# HSI_TOP register map
Vendor: Texas Instruments
Peripheral module from a debugger description file (folder omap4460).
Registers are 32-bit, access per field, reset 0x0 unless marked. A register's access mark holds for its fields unless they carry their own. Offsets are as the file gives them; lines under a group give offsets from that group; [hi:lo] are bit positions; {n}, {i} and the like mark numbered series; 'fields as' and 'values as' point back to an identical list; <NAME> marks a mode.

## HSI_TOP
0x00 HSI_REVISION ro reset not defined — IP Revision Identifier (X.Y.R)Used by software to track features, bugs, and compatibility
  [31:0] REVISION — IP Revision
0x04 HSI_HWINFO ro reset not defined — Information about the IP module's hardware configuration, i.e. typically the module's HDL generics (if any).Actual field format and encoding is decided by the module's designer.
  [31:0] HWINFO — IP module hardware configuration
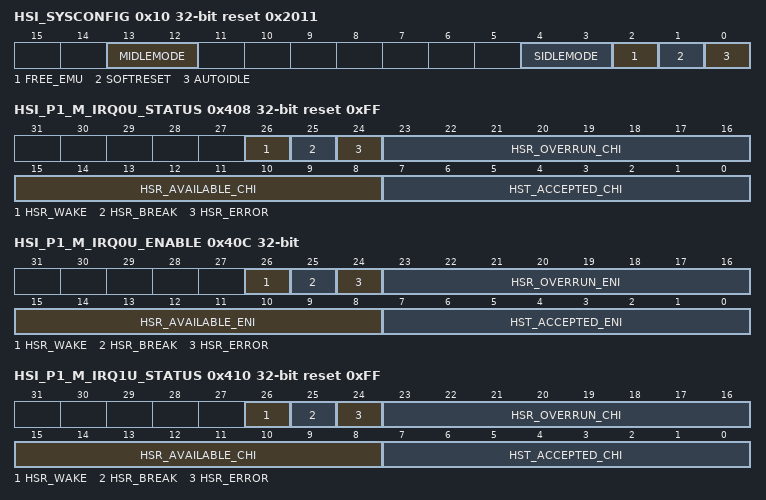
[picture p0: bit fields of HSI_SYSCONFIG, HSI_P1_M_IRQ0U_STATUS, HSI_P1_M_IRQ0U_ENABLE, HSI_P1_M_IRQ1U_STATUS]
0x10 HSI_SYSCONFIG reset 0x2011 — This register allows controlling various parameters of the L4_CFG interface
  [13:12] MIDLEMODE rw — Master interface power management, standby/wait control
    0=force standby; 1=no standby; 2=smart standby; 3=smart standby wakeup
  [4:3] SIDLEMODE rw — Slave interface power management, request/acknowledgement control
    0=force idle; 1=no idle; 2=smart idle; 3=smart idle wakeup
  [2] FREE_EMU rw — Sensitivity to emulation (debug) suspend input signal
    0=module is sensitive to emulation suspend; 1=module is not sensitive to emulation suspend
  [1] SOFTRESET rw — Software reset
    0=no reset applied; 1=Software reset applied
  [0] AUTOIDLE rw — Internal interface clock gating strategy
    0=interface clock is free-running; 1=automatic interface clock gating strategy, based on interconnect interface activity
0x14 HSI_SYSSTATUS ro reset 0x1 — Status on module, (reset done on bit 0, available for more status info)
  [31:0] RESETDONE — Internal reset monitoring
    0=RESETDONE_0_r (internal reset is ongoing); 1=RESETDONE_1_r (internal reset is completed and the module is ready to be used)
0x408 HSI_P1_M_IRQ0U_STATUS reset 0xFF — IRQ status register for FIFO (8..15) events and for port p break, wake and error events. Events will signal interrupt for DSP line r (Dspirq_r)Read 0: event has not occurredRead 1: event has occurredWrite 0: bit stays unchangedWrite 1: bit gets reset to 0
  [26] HSR_WAKE rw — Wake detected on any channel 8..15
  [25] HSR_BREAK rw — Break detected on any channel 8..15
  [24] HSR_ERROR rw — Error detected on any channel 8..15
  [23:16] HSR_OVERRUN_CHI rw — Data overrun in real time mode channel 8..15 (LSB stands for channel 8 and MSB for channel 15).
  [15:8] HSR_AVAILABLE_CHI rw — Data received on channel 8..15 (LSB stands for channel 8 and MSB for channel 15)
  [7:0] HST_ACCEPTED_CHI rw — Data transmitted on channel 8..15 (LSB stands for channel 8 and MSB for channel 15)
0x40C HSI_P1_M_IRQ0U_ENABLE — IRQ enable register for FIFO (8..15) events and for port p break, wake and error events signaled to DSP line r (Dspirq_r)Write 0: event is maskedWrite 1: event is enabled
  [26] HSR_WAKE rw — Wake interrupt enable for all channels 8..15
  [25] HSR_BREAK rw — Break interrupt enable for all channels 8..15
  [24] HSR_ERROR rw — Error interrupt enable for all channels 8..15
  [23:16] HSR_OVERRUN_ENI rw — Overrun interrupt enable for channel 8..15 (LSB stands for channel 8 and MSB for channel 15)
  [15:8] HSR_AVAILABLE_ENI rw — Data available interrupt enable for channel 8..15 (LSB stands for channel 8 and MSB for channel 15)
  [7:0] HST_ACCEPTED_ENI rw — Data accepted interrupt enable for channel 8..15 (LSB stands for channel 8 and MSB for channel 15)
0x410 HSI_P1_M_IRQ1U_STATUS reset 0xFF — IRQ status register for FIFO (8..15) events and for port p break, wake and error events. Events will signal interrupt for DSP line r (Dspirq_r)Read 0: event has not occurredRead 1: event has occurredWrite 0: bit stays unchangedWrite 1: bit gets reset to 0
  fields as HSI_P1_M_IRQ0U_STATUS
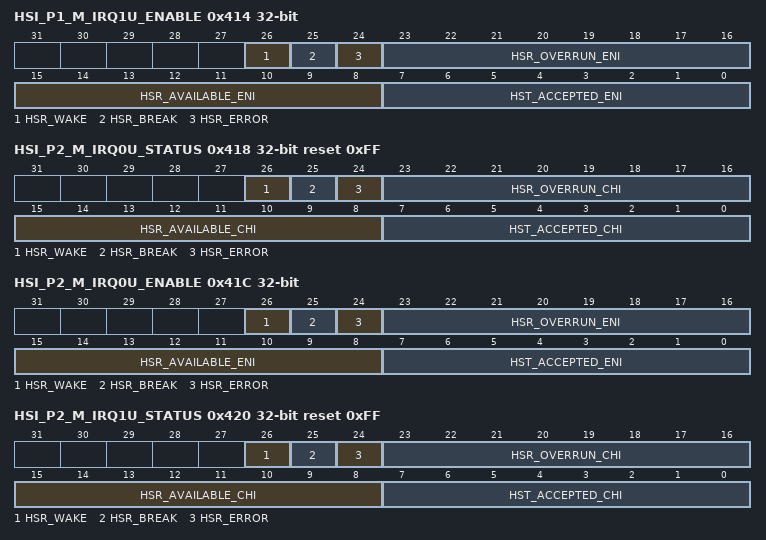
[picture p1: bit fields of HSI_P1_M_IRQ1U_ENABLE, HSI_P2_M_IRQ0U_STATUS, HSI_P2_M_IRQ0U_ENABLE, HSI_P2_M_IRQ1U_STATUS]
0x414 HSI_P1_M_IRQ1U_ENABLE — IRQ enable register for FIFO (8..15) events and for port p break, wake and error events signaled to DSP line r (Dspirq_r)Write 0: event is maskedWrite 1: event is enabled
  fields as HSI_P1_M_IRQ0U_ENABLE
0x418 HSI_P2_M_IRQ0U_STATUS reset 0xFF — IRQ status register for FIFO (8..15) events and for port p break, wake and error events. Events will signal interrupt for DSP line r (Dspirq_r)Read 0: event has not occurredRead 1: event has occurredWrite 0: bit stays unchangedWrite 1: bit gets reset to 0
  fields as HSI_P1_M_IRQ0U_STATUS
0x41C HSI_P2_M_IRQ0U_ENABLE — IRQ enable register for FIFO (8..15) events and for port p break, wake and error events signaled to DSP line r (Dspirq_r)Write 0: event is maskedWrite 1: event is enabled
  fields as HSI_P1_M_IRQ0U_ENABLE
0x420 HSI_P2_M_IRQ1U_STATUS reset 0xFF — IRQ status register for FIFO (8..15) events and for port p break, wake and error events. Events will signal interrupt for DSP line r (Dspirq_r)Read 0: event has not occurredRead 1: event has occurredWrite 0: bit stays unchangedWrite 1: bit gets reset to 0
  fields as HSI_P1_M_IRQ0U_STATUS
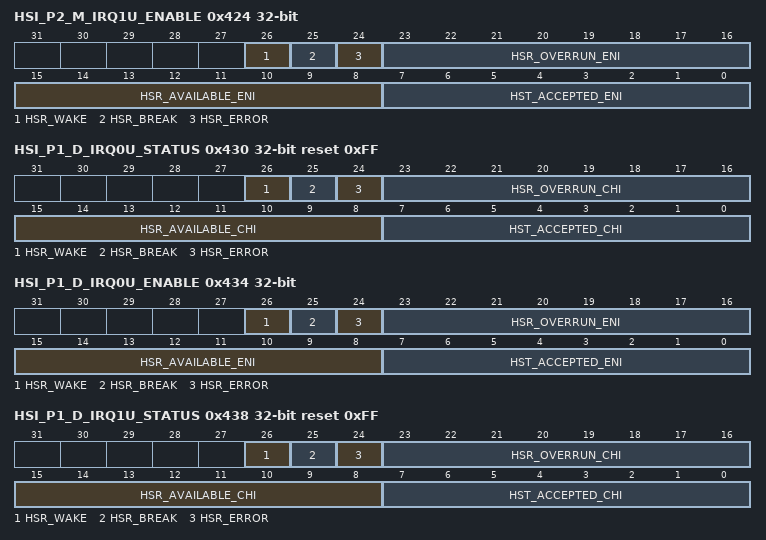
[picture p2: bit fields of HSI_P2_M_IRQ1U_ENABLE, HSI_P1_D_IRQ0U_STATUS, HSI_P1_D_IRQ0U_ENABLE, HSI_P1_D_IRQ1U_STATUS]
0x424 HSI_P2_M_IRQ1U_ENABLE — IRQ enable register for FIFO (8..15) events and for port p break, wake and error events signaled to DSP line r (Dspirq_r)Write 0: event is maskedWrite 1: event is enabled
  fields as HSI_P1_M_IRQ0U_ENABLE
0x430 HSI_P1_D_IRQ0U_STATUS reset 0xFF — IRQ status register for FIFO (8..15) events and for port p break, wake and error events. Events will signal interrupt for DSP line r (Dspirq_r)Read 0: event has not occurredRead 1: event has occurredWrite 0: bit stays unchangedWrite 1: bit gets reset to 0
  [26] HSR_WAKE rw — Wake detected on any channel 8..15
  [25] HSR_BREAK rw — Break detected on any channel 8..15
  [24] HSR_ERROR rw — Error on any channel 8..15
  [23:16] HSR_OVERRUN_CHI rw — Data overrun in real time mode channel 8..15 (LSB stands for channel 8 and MSB for channel 15)
  [15:8] HSR_AVAILABLE_CHI rw — Data received on channel 8..15 (LSB stands for channel 8 and MSB for channel 15)
  [7:0] HST_ACCEPTED_CHI rw — Data transmitted on channel 8..15 (LSB stands for channel 8 and MSB for channel 15)
0x434 HSI_P1_D_IRQ0U_ENABLE — IRQ enable register for FIFO (8..15) events and for port p break, wake and error events signaled to DSP line r (Dspirq_r)Write 0: event is maskedWrite 1: event is enabled
  [26] HSR_WAKE rw — Wake interrupt enable for channel 8..15
  [25] HSR_BREAK rw — Break interrupt enable for channel 8..15
  [24] HSR_ERROR rw — Error interrupt enable for channel 8..15
  [23:16] HSR_OVERRUN_ENI rw — Overrun interrupt enable for channel 8..15
  [15:8] HSR_AVAILABLE_ENI rw — Data available interrupt enable for channel 8..15 (LSB stands for channel 8 and MSB for channel 15)
  [7:0] HST_ACCEPTED_ENI rw — Data accepted interrupt enable for channel 8..15 (LSB stands for channel 8 and MSB for channel 15)
0x438 HSI_P1_D_IRQ1U_STATUS reset 0xFF — IRQ status register for FIFO (8..15) events and for port p break, wake and error events. Events will signal interrupt for DSP line r (Dspirq_r)Read 0: event has not occurredRead 1: event has occurredWrite 0: bit stays unchangedWrite 1: bit gets reset to 0
  fields as HSI_P1_D_IRQ0U_STATUS
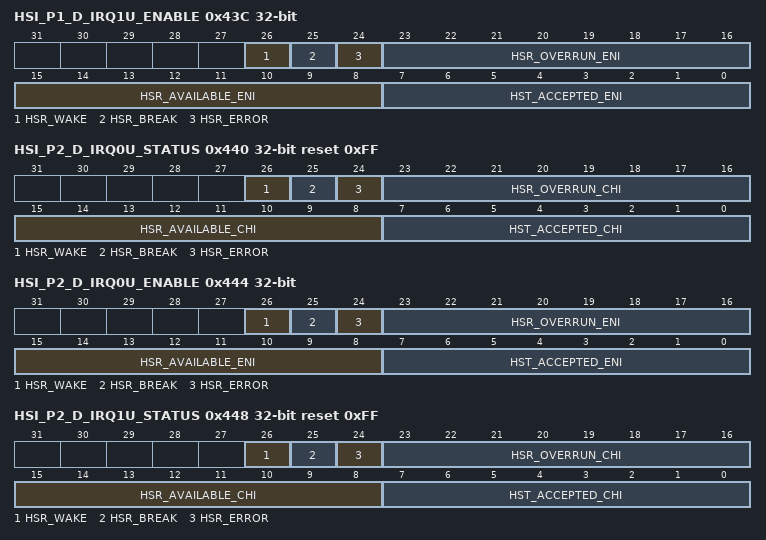
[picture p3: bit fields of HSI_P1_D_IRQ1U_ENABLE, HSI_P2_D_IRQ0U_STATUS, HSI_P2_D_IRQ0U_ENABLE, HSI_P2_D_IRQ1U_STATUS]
0x43C HSI_P1_D_IRQ1U_ENABLE — IRQ enable register for FIFO (8..15) events and for port p break, wake and error events signaled to DSP line r (Dspirq_r)Write 0: event is maskedWrite 1: event is enabled
  fields as HSI_P1_D_IRQ0U_ENABLE
0x440 HSI_P2_D_IRQ0U_STATUS reset 0xFF — IRQ status register for FIFO (8..15) events and for port p break, wake and error events. Events will signal interrupt for DSP line r (Dspirq_r)Read 0: event has not occurredRead 1: event has occurredWrite 0: bit stays unchangedWrite 1: bit gets reset to 0
  fields as HSI_P1_D_IRQ0U_STATUS
0x444 HSI_P2_D_IRQ0U_ENABLE — IRQ enable register for FIFO (8..15) events and for port p break, wake and error events signaled to DSP line r (Dspirq_r)Write 0: event is maskedWrite 1: event is enabled
  fields as HSI_P1_D_IRQ0U_ENABLE
0x448 HSI_P2_D_IRQ1U_STATUS reset 0xFF — IRQ status register for FIFO (8..15) events and for port p break, wake and error events. Events will signal interrupt for DSP line r (Dspirq_r)Read 0: event has not occurredRead 1: event has occurredWrite 0: bit stays unchangedWrite 1: bit gets reset to 0
  fields as HSI_P1_D_IRQ0U_STATUS
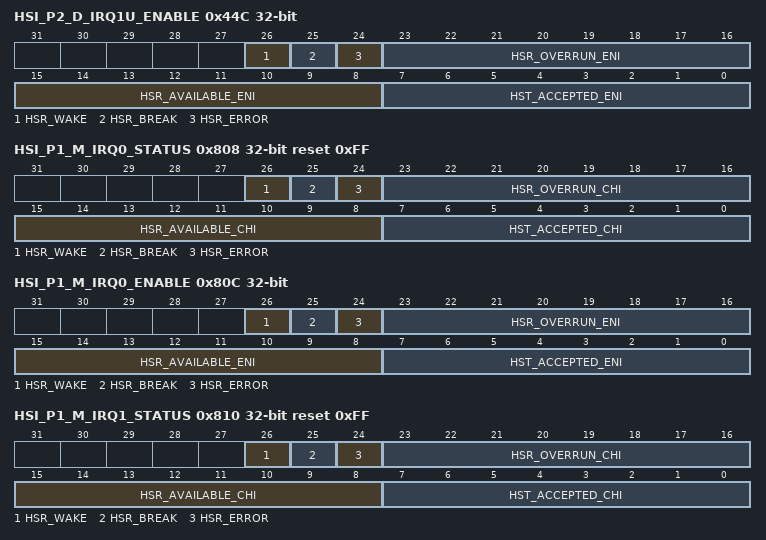
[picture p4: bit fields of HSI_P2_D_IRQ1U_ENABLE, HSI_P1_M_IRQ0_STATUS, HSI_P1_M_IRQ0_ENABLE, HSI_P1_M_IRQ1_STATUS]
0x44C HSI_P2_D_IRQ1U_ENABLE — IRQ enable register for FIFO (8..15) events and for port p break, wake and error events signaled to DSP line r (Dspirq_r)Write 0: event is maskedWrite 1: event is enabled
  fields as HSI_P1_D_IRQ0U_ENABLE
0x800 HSI_DMA_M_IRQSTATUS — This register collects status for all of the DMA events able to generate interrupt to MPU:Read 0: event has not occurredRead 1: event has occurredWrite 0: bit stays unchangedWrite 1: bit gets reset to 0
  [15:0] DMA_CHI rw — Channel i status (LSB stands for channel 0 and MSB for channel 15)
0x804 HSI_DMA_M_IRQENABLE — This register masks and unmasks DMA sources of interrupt to MPU:Write 0: event is maskedWrite 1: event is enabled
  [15:0] DMA_EN_CHI rw — Channel i (LSB stands for channel 0 and MSB for channel 15)
0x808 HSI_P1_M_IRQ0_STATUS reset 0xFF — IRQ status register for FIFO (0..7) events and for port p break, wake and error events Events will signal interrupt for MPU line r (Mpuirq_r)Read 0: event has not occurredRead 1: event has occurredWrite 0: bit stays unchangedWrite 1: bit gets reset to 0
  [26] HSR_WAKE rw — Wake detected on Port p
  [25] HSR_BREAK rw — Break detected on Port p
  [24] HSR_ERROR rw — Error on Port p
  [23:16] HSR_OVERRUN_CHI rw — Data overrun in real time mode channel 0..7 (LSB stands for channel 0 and MSB for channel 7)
  [15:8] HSR_AVAILABLE_CHI rw — Data received on channel 0..7 (LSB stands for channel 0 and MSB for channel 7)
  [7:0] HST_ACCEPTED_CHI rw — Data transmitted on channel 0..7 (LSB stands for channel 0 and MSB for channel 7)
0x80C HSI_P1_M_IRQ0_ENABLE — IRQ enable register for FIFO (0..7) events and for port p break, wake and error events signaled to MPU line r (Mpuirq_r).Write 0: event is maskedWrite 1: event is enabled
  [26] HSR_WAKE rw — Wake interrupt enable for Port p
  [25] HSR_BREAK rw — Break interrupt enable for Port p
  [24] HSR_ERROR rw — Error interrupt enable for Port p
  [23:16] HSR_OVERRUN_ENI rw — Overrun interrupt enable for channel 0..7 (LSB stands for channel 0 and MSB for channel 7)
  [15:8] HSR_AVAILABLE_ENI rw — Data available interrupt enable for channel 0..7 (LSB stands for channel 0 and MSB for channel 7)
  [7:0] HST_ACCEPTED_ENI rw — Data accepted interrupt enable for channel 0..7 (LSB stands for channel 0 and MSB for channel 7)
0x810 HSI_P1_M_IRQ1_STATUS reset 0xFF — IRQ status register for FIFO (0..7) events and for port p break, wake and error events Events will signal interrupt for MPU line r (Mpuirq_r)Read 0: event has not occurredRead 1: event has occurredWrite 0: bit stays unchangedWrite 1: bit gets reset to 0
  fields as HSI_P1_M_IRQ0_STATUS
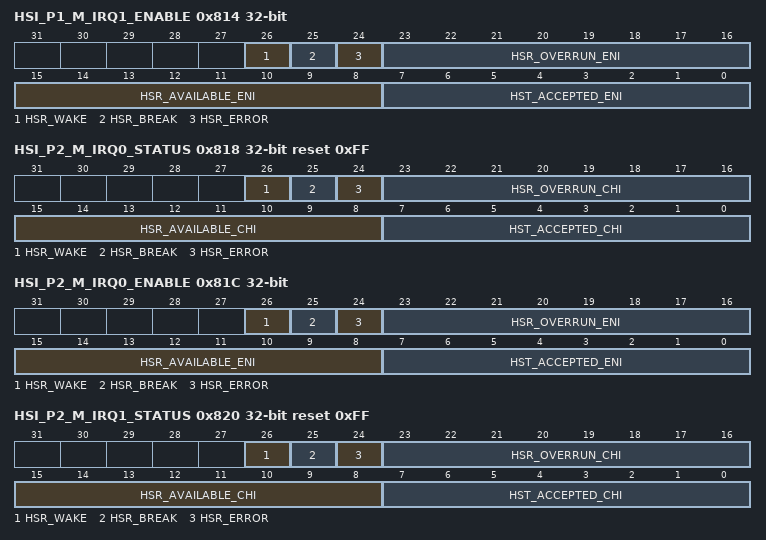
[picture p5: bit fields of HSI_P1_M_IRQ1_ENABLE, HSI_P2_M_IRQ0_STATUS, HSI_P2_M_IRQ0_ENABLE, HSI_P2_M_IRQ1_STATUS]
0x814 HSI_P1_M_IRQ1_ENABLE — IRQ enable register for FIFO (0..7) events and for port p break, wake and error events signaled to MPU line r (Mpuirq_r).Write 0: event is maskedWrite 1: event is enabled
  fields as HSI_P1_M_IRQ0_ENABLE
0x818 HSI_P2_M_IRQ0_STATUS reset 0xFF — IRQ status register for FIFO (0..7) events and for port p break, wake and error events Events will signal interrupt for MPU line r (Mpuirq_r)Read 0: event has not occurredRead 1: event has occurredWrite 0: bit stays unchangedWrite 1: bit gets reset to 0
  fields as HSI_P1_M_IRQ0_STATUS
0x81C HSI_P2_M_IRQ0_ENABLE — IRQ enable register for FIFO (0..7) events and for port p break, wake and error events signaled to MPU line r (Mpuirq_r).Write 0: event is maskedWrite 1: event is enabled
  fields as HSI_P1_M_IRQ0_ENABLE
0x820 HSI_P2_M_IRQ1_STATUS reset 0xFF — IRQ status register for FIFO (0..7) events and for port p break, wake and error events Events will signal interrupt for MPU line r (Mpuirq_r)Read 0: event has not occurredRead 1: event has occurredWrite 0: bit stays unchangedWrite 1: bit gets reset to 0
  fields as HSI_P1_M_IRQ0_STATUS
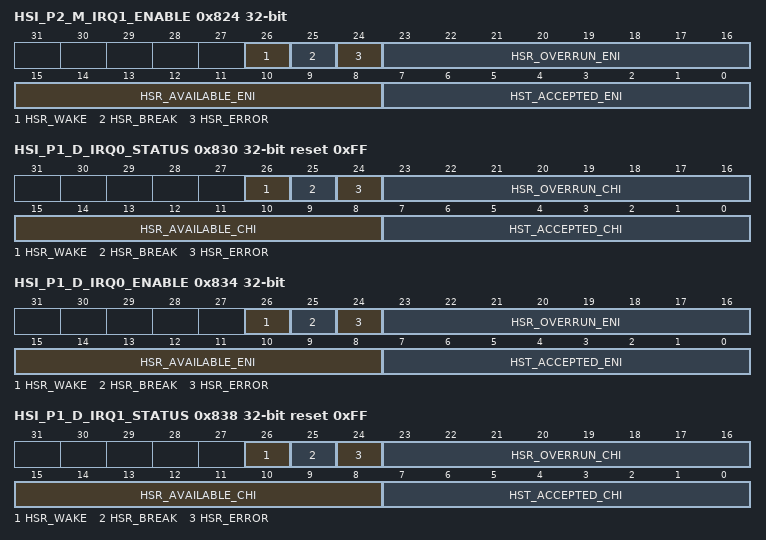
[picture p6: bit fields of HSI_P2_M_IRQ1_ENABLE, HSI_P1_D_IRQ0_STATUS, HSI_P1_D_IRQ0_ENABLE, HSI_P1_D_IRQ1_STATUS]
0x824 HSI_P2_M_IRQ1_ENABLE — IRQ enable register for FIFO (0..7) events and for port p break, wake and error events signaled to MPU line r (Mpuirq_r).Write 0: event is maskedWrite 1: event is enabled
  fields as HSI_P1_M_IRQ0_ENABLE
0x828 HSI_DMA_D_IRQSTATUS — IRQ status register for all DMA events. Events will generate interrupt for DSP.Read 0: event has not occurredRead 1: event has occurredWrite 0: bit stays unchangedWrite 1: bit gets reset to 0
  [15:0] DMA_CHI rw — IRQ event happened on DMA channel i (LSB stands for channel 0 and MSB for channel 15)
0x82C HSI_DMA_D_IRQENABLE — IRQ enable register for all DMA events signaled to DSP..Write 0: event is maskedWrite 1: event is enabled
  fields as HSI_DMA_M_IRQENABLE
0x830 HSI_P1_D_IRQ0_STATUS reset 0xFF — IRQ status register for FIFO (0..7) events and for port p break, wake and error events. Events will signal interrupt for DSP line r (Dspirq_r).Read 0: event has not occurredRead 1: event has occurredWrite 0: bit stays unchangedWrite 1: bit gets reset to 0
  fields as HSI_P1_M_IRQ0_STATUS
0x834 HSI_P1_D_IRQ0_ENABLE — IRQ enable register for FIFO (0..7) events and for port p break, wake and error events signaled to DSP line r (Dspirq_r)Write 0: event is maskedWrite 1: event is enabled
  fields as HSI_P1_M_IRQ0_ENABLE
0x838 HSI_P1_D_IRQ1_STATUS reset 0xFF — IRQ status register for FIFO (0..7) events and for port p break, wake and error events. Events will signal interrupt for DSP line r (Dspirq_r).Read 0: event has not occurredRead 1: event has occurredWrite 0: bit stays unchangedWrite 1: bit gets reset to 0
  fields as HSI_P1_M_IRQ0_STATUS
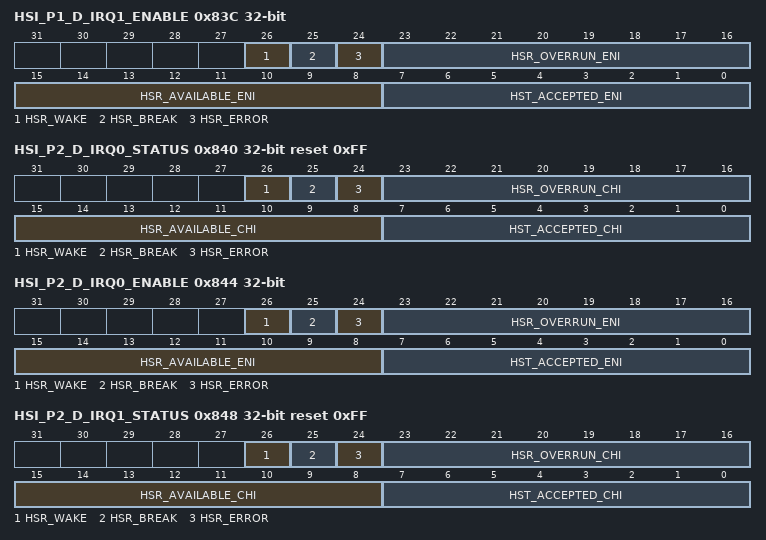
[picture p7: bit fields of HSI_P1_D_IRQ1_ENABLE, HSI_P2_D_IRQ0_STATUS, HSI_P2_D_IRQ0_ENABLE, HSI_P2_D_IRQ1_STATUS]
0x83C HSI_P1_D_IRQ1_ENABLE — IRQ enable register for FIFO (0..7) events and for port p break, wake and error events signaled to DSP line r (Dspirq_r)Write 0: event is maskedWrite 1: event is enabled
  fields as HSI_P1_M_IRQ0_ENABLE
0x840 HSI_P2_D_IRQ0_STATUS reset 0xFF — IRQ status register for FIFO (0..7) events and for port p break, wake and error events. Events will signal interrupt for DSP line r (Dspirq_r).Read 0: event has not occurredRead 1: event has occurredWrite 0: bit stays unchangedWrite 1: bit gets reset to 0
  fields as HSI_P1_M_IRQ0_STATUS
0x844 HSI_P2_D_IRQ0_ENABLE — IRQ enable register for FIFO (0..7) events and for port p break, wake and error events signaled to DSP line r (Dspirq_r)Write 0: event is maskedWrite 1: event is enabled
  fields as HSI_P1_M_IRQ0_ENABLE
0x848 HSI_P2_D_IRQ1_STATUS reset 0xFF — IRQ status register for FIFO (0..7) events and for port p break, wake and error events. Events will signal interrupt for DSP line r (Dspirq_r).Read 0: event has not occurredRead 1: event has occurredWrite 0: bit stays unchangedWrite 1: bit gets reset to 0
  fields as HSI_P1_M_IRQ0_STATUS
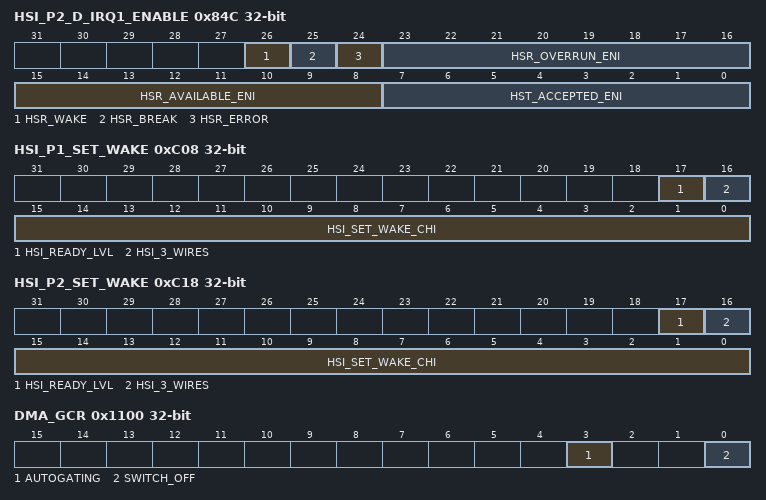
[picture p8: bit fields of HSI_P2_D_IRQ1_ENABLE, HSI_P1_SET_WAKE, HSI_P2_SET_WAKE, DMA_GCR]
0x84C HSI_P2_D_IRQ1_ENABLE — IRQ enable register for FIFO (0..7) events and for port p break, wake and error events signaled to DSP line r (Dspirq_r)Write 0: event is maskedWrite 1: event is enabled
  fields as HSI_P1_M_IRQ0_ENABLE
0xC00 HSI_P1_WAKE ro — Programmed wake state for each channel, in port 10x0: no channel wakeup on WAKE line requested0x1: channel wakeup requested
  [15:0] HSI_WAKE_CHI — Channel 0..15 (LSB stands for channel 0 and MSB for channel 15)
0xC04 HSI_P1_CLEAR_WAKE — Clear register for programmed wake state on port 1 HST_WAKE for each channel0x0: no effect0x1: clears bit
  [15:0] HSI_CLEAR_WAKE_CHI wo — Channel 0..15 (LSB stands for channel 0 and MSB for channel 15)
0xC08 HSI_P1_SET_WAKE — Set function for wake state for each channel, in port 10x0: no effect0x1: sets bit
  [17] HSI_READY_LVL rw — READY default level
    0=READY defaults to 0; 1=READY defaults to 1
  [16] HSI_3_WIRES rw — Sets 3 wires behavior
    0=sets 4 wires behavior (wakeup with WAKE signal); 1=sets 3 wire behavior (wakeup on line activity without WAKE signal)
  [15:0] HSI_SET_WAKE_CHI wo — Sets programmed WAKE state for channel i
    0=HSI_SET_WAKE_CHI_0_w (no effect); 1=HSI_SET_WAKE_CHI_1_w (sets bit)
0xC10 HSI_P2_WAKE ro — Programmed wake state for each channel, in port 20x0: no channel wakeup on WAKE line requested0x1: channel wakeup requested
  fields as HSI_P1_WAKE
0xC14 HSI_P2_CLEAR_WAKE — Clear register for programmed wake state on port 2 HST_WAKE for each channel0x0: no effect0x1: clears bit
  fields as HSI_P1_CLEAR_WAKE
0xC18 HSI_P2_SET_WAKE — Set function for wake state for each channel, in port 20x0: no effect0x1: sets bit
  fields as HSI_P1_SET_WAKE
0x1100 DMA_GCR — Global Control Register: suspend and clock gating
  [3] AUTOGATING rw — DMA clock autogating enable
    0=no DMA clock control; 1=DMA clock control
  [0] SWITCH_OFF rw — DMA global clock control
    0=DMA Clock released; 1=DMA Clock cutoff
0x1200 DMA_GRST — DMA software reset control register
  [0] SWRESET rw — DMA sw reset control bit
    1=writing 1 resets the DMA. It is automatically reset to 0 by hardware once software reset is done
